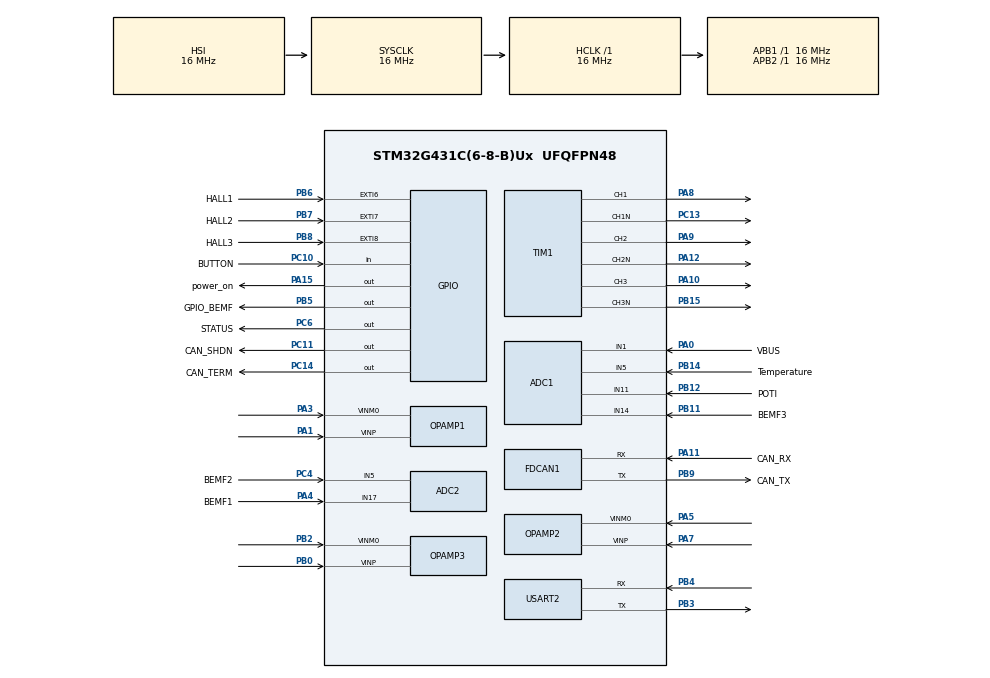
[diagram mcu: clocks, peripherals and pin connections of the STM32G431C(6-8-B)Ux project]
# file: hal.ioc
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ADC1.DMAAccessModeView=ENABLE
ADC1.DMAContinuousRequests=ENABLE
ADC1.DataAlign=ADC_DATAALIGN_LEFT
ADC1.EOCSelection=ADC_EOC_SEQ_CONV
ADC1.ExternalTrigConv=ADC_EXTERNALTRIG_T1_TRGO
ADC1.Mode=ADC_DUALMODE_REGSIMULT
ADC1.NbrOfConversionFlag=1
ADC1.Overrun=ADC_OVR_DATA_OVERWRITTEN
ADC1.master=1
ADC2.Channel-0\#ChannelRegularConversion=ADC_CHANNEL_5
ADC2.DMAAccessModeView=ENABLE
ADC2.DMAContinuousRequests=ENABLE
ADC2.DataAlign=ADC_DATAALIGN_LEFT
ADC2.EOCSelection=ADC_EOC_SINGLE_CONV
ADC2.Mode=ADC_DUALMODE_REGSIMULT
ADC2.NbrOfConversionFlag=1
Dma.ADC1.0.Direction=DMA_PERIPH_TO_MEMORY
Dma.ADC1.0.EventEnable=DISABLE
Dma.ADC1.0.Instance=DMA1_Channel1
Dma.ADC1.0.MemDataAlignment=DMA_MDATAALIGN_HALFWORD
Dma.ADC1.0.MemInc=DMA_MINC_ENABLE
Dma.ADC1.0.Mode=DMA_CIRCULAR
Dma.ADC1.0.PeriphDataAlignment=DMA_PDATAALIGN_HALFWORD
Dma.ADC1.0.PeriphInc=DMA_PINC_DISABLE
Dma.ADC1.0.Polarity=HAL_DMAMUX_REQ_GEN_RISING
Dma.ADC1.0.Priority=DMA_PRIORITY_LOW
Dma.ADC1.0.RequestNumber=1
Dma.ADC1.0.SignalID=NONE
Dma.ADC1.0.SyncEnable=DISABLE
Dma.ADC1.0.SyncPolarity=HAL_DMAMUX_SYNC_NO_EVENT
Dma.ADC1.0.SyncRequestNumber=1
Dma.ADC1.0.SyncSignalID=NONE
Dma.ADC2.1.Direction=DMA_PERIPH_TO_MEMORY
Dma.ADC2.1.EventEnable=DISABLE
Dma.ADC2.1.Instance=DMA1_Channel2
Dma.ADC2.1.MemDataAlignment=DMA_MDATAALIGN_HALFWORD
Dma.ADC2.1.MemInc=DMA_MINC_ENABLE
Dma.ADC2.1.Mode=DMA_CIRCULAR
Dma.ADC2.1.PeriphDataAlignment=DMA_PDATAALIGN_HALFWORD
Dma.ADC2.1.PeriphInc=DMA_PINC_DISABLE
Dma.ADC2.1.Polarity=HAL_DMAMUX_REQ_GEN_RISING
Dma.ADC2.1.Priority=DMA_PRIORITY_LOW
Dma.ADC2.1.RequestNumber=1
Dma.ADC2.1.SignalID=NONE
Dma.ADC2.1.SyncEnable=DISABLE
Dma.ADC2.1.SyncPolarity=HAL_DMAMUX_SYNC_NO_EVENT
Dma.ADC2.1.SyncRequestNumber=1
Dma.ADC2.1.SyncSignalID=NONE
Dma.Request0=ADC1
Dma.Request1=ADC2
Dma.Request2=USART2_RX
Dma.Request3=USART2_TX
Dma.USART2_RX.2.Direction=DMA_PERIPH_TO_MEMORY
Dma.USART2_RX.2.EventEnable=DISABLE
Dma.USART2_RX.2.Instance=DMA1_Channel3
Dma.USART2_RX.2.MemDataAlignment=DMA_MDATAALIGN_BYTE
Dma.USART2_RX.2.MemInc=DMA_MINC_ENABLE
Dma.USART2_RX.2.Mode=DMA_NORMAL
Dma.USART2_RX.2.PeriphDataAlignment=DMA_PDATAALIGN_BYTE
Dma.USART2_RX.2.PeriphInc=DMA_PINC_DISABLE
Dma.USART2_RX.2.Polarity=HAL_DMAMUX_REQ_GEN_RISING
Dma.USART2_RX.2.Priority=DMA_PRIORITY_LOW
Dma.USART2_RX.2.RequestNumber=1
Dma.USART2_RX.2.SignalID=NONE
Dma.USART2_RX.2.SyncEnable=DISABLE
Dma.USART2_RX.2.SyncPolarity=HAL_DMAMUX_SYNC_NO_EVENT
Dma.USART2_RX.2.SyncRequestNumber=1
Dma.USART2_RX.2.SyncSignalID=NONE
Dma.USART2_TX.3.Direction=DMA_MEMORY_TO_PERIPH
Dma.USART2_TX.3.EventEnable=DISABLE
Dma.USART2_TX.3.Instance=DMA1_Channel4
Dma.USART2_TX.3.MemDataAlignment=DMA_MDATAALIGN_BYTE
Dma.USART2_TX.3.MemInc=DMA_MINC_ENABLE
Dma.USART2_TX.3.Mode=DMA_NORMAL
Dma.USART2_TX.3.PeriphDataAlignment=DMA_PDATAALIGN_BYTE
Dma.USART2_TX.3.PeriphInc=DMA_PINC_DISABLE
Dma.USART2_TX.3.Polarity=HAL_DMAMUX_REQ_GEN_RISING
Dma.USART2_TX.3.Priority=DMA_PRIORITY_LOW
Dma.USART2_TX.3.RequestNumber=1
Dma.USART2_TX.3.SignalID=NONE
Dma.USART2_TX.3.SyncEnable=DISABLE
Dma.USART2_TX.3.SyncPolarity=HAL_DMAMUX_SYNC_NO_EVENT
Dma.USART2_TX.3.SyncRequestNumber=1
Dma.USART2_TX.3.SyncSignalID=NONE
FDCAN1.CalculateBaudRateNominal=333333
FDCAN1.CalculateTimeBitNominal=3000
FDCAN1.CalculateTimeQuantumNominal=1000.0
Mcu.Family=STM32G4
Mcu.Name=STM32G431C(6-8-B)Ux
Mcu.Package=UFQFPN48
NVIC.ADC1_2_IRQn=true\:0\:0\:false\:false\:true\:true\:true\:true
NVIC.DMA1_Channel1_IRQn=true\:0\:0\:false\:false\:true\:false\:true\:true
NVIC.DMA1_Channel2_IRQn=true\:0\:0\:false\:false\:true\:false\:true\:true
NVIC.DMA1_Channel3_IRQn=true\:0\:0\:false\:false\:true\:false\:true\:true
NVIC.DMA1_Channel4_IRQn=true\:0\:0\:false\:false\:true\:false\:true\:true
NVIC.EXTI9_5_IRQn=true\:0\:0\:false\:false\:true\:true\:true\:true
NVIC.PriorityGroup=NVIC_PRIORITYGROUP_4
NVIC.TIM1_UP_TIM16_IRQn=true\:0\:0\:false\:false\:true\:true\:true\:true
NVIC.USART2_IRQn=true\:0\:0\:false\:false\:true\:true\:true\:true
PA0.GPIO_Label=VBUS
PA0.GPIO_Mode=GPIO_MODE_ANALOG
PA0.GPIO_PuPd=GPIO_NOPULL
PA0.Mode=IN1-Single-Ended
PA0.Signal=ADC1_IN1
PA1.Mode=standalone Internally connected_IO
PA1.Signal=OPAMP1_VINP
PA10.GPIO_PuPd=GPIO_PULLDOWN
PA10.Signal=S_TIM1_CH3
PA11.GPIO_Label=CAN_RX
PA11.Mode=FDCAN_Activate
PA11.Signal=FDCAN1_RX
PA12.GPIO_PuPd=GPIO_PULLDOWN
PA12.Mode=PWM Generation2 CH2 CH2N
PA12.Signal=TIM1_CH2N
PA13.Signal=SYS_JTMS-SWDIO
PA14.Signal=SYS_JTCK-SWCLK
PA15.GPIO_Label=power_on
PA15.GPIO_ModeDefaultOutputPP=GPIO_MODE_OUTPUT_OD
PA15.GPIO_PuPd=GPIO_NOPULL
PA15.PinState=GPIO_PIN_SET
PA15.Signal=GPIO_Output
PA3.Mode=standalone Internally connected_IO
PA3.Signal=OPAMP1_VINM0
PA4.GPIO_Label=BEMF1
PA4.GPIO_Mode=GPIO_MODE_ANALOG
PA4.GPIO_PuPd=GPIO_NOPULL
PA4.Mode=IN17-Single-Ended
PA4.Signal=ADC2_IN17
PA5.Mode=standalone Internally connected_IO
PA5.Signal=OPAMP2_VINM0
PA7.Mode=standalone Internally connected_IO
PA7.Signal=OPAMP2_VINP
PA8.GPIO_PuPd=GPIO_PULLDOWN
PA8.Signal=S_TIM1_CH1
PA9.GPIO_PuPd=GPIO_PULLDOWN
PA9.Signal=S_TIM1_CH2
PB0.Mode=standalone Internally connected_IO
PB0.Signal=OPAMP3_VINP
PB11.GPIO_Label=BEMF3
PB11.GPIO_Mode=GPIO_MODE_ANALOG
PB11.GPIO_PuPd=GPIO_NOPULL
PB11.Mode=IN14-Single-Ended
PB11.Signal=ADC1_IN14
PB12.GPIO_Label=POTI
PB12.GPIO_Mode=GPIO_MODE_ANALOG
PB12.GPIO_PuPd=GPIO_NOPULL
PB12.Mode=IN11-Single-Ended
PB12.Signal=ADC1_IN11
PB14.GPIO_Label=Temperature
PB14.GPIO_Mode=GPIO_MODE_ANALOG
PB14.GPIO_PuPd=GPIO_NOPULL
PB14.Mode=IN5-Single-Ended
PB14.Signal=ADC1_IN5
PB15.GPIO_PuPd=GPIO_PULLDOWN
PB15.Mode=PWM Generation3 CH3 CH3N
PB15.Signal=TIM1_CH3N
PB2.Mode=standalone Internally connected_IO
PB2.Signal=OPAMP3_VINM0
PB3.Mode=Asynchronous
PB3.Signal=USART2_TX
PB4.Mode=Asynchronous
PB4.Signal=USART2_RX
PB5.GPIO_Label=GPIO_BEMF
PB5.Signal=GPIO_Output
PB6.GPIO_Label=HALL1
PB6.GPIO_ModeDefaultEXTI=GPIO_MODE_IT_RISING_FALLING
PB6.Signal=GPXTI6
PB7.GPIO_Label=HALL2
PB7.GPIO_ModeDefaultEXTI=GPIO_MODE_IT_RISING_FALLING
PB7.Signal=GPXTI7
PB8-BOOT0.GPIO_Label=HALL3
PB8-BOOT0.GPIO_ModeDefaultEXTI=GPIO_MODE_IT_RISING_FALLING
PB8-BOOT0.Signal=GPXTI8
PB9.GPIO_Label=CAN_TX
PB9.Mode=FDCAN_Activate
PB9.Signal=FDCAN1_TX
PC10.GPIO_Label=BUTTON
PC10.Signal=GPIO_Input
PC11.GPIO_Label=CAN_SHDN
PC11.Signal=GPIO_Output
PC13.GPIO_PuPd=GPIO_PULLDOWN
PC13.Mode=PWM Generation1 CH1 CH1N
PC13.Signal=TIM1_CH1N
PC14-OSC32_IN.GPIO_Label=CAN_TERM
PC14-OSC32_IN.Signal=GPIO_Output
PC4.GPIO_Label=BEMF2
PC4.GPIO_Mode=GPIO_MODE_ANALOG
PC4.GPIO_PuPd=GPIO_NOPULL
PC4.Mode=IN5-Single-Ended
PC4.Signal=ADC2_IN5
PC6.GPIO_Label=STATUS
PC6.Signal=GPIO_Output
PF0-OSC_IN.Mode=HSE-External-Oscillator
PF0-OSC_IN.Signal=RCC_OSC_IN
PF1-OSC_OUT.Mode=HSE-External-Oscillator
PF1-OSC_OUT.Signal=RCC_OSC_OUT
ProjectManager.HeapSize=0x200
ProjectManager.StackSize=0x400
ProjectManager.TargetToolchain=CMake
RCC.ADC12Freq_Value=16000000
RCC.AHBFreq_Value=16000000
RCC.APB1Freq_Value=16000000
RCC.APB1TimFreq_Value=16000000
RCC.APB2Freq_Value=16000000
RCC.APB2TimFreq_Value=16000000
RCC.CortexFreq_Value=16000000
RCC.EXTERNAL_CLOCK_VALUE=12288000
RCC.HCLKFreq_Value=16000000
RCC.HSE_VALUE=8000000
RCC.HSI48_VALUE=48000000
RCC.HSI_VALUE=16000000
RCC.LSE_VALUE=32768
RCC.PLLM=RCC_PLLM_DIV4
RCC.PLLN=85
RCC.SYSCLKFreq_VALUE=16000000
RCC.USBFreq_Value=170000000
RCC.VCOOutputFreq_Value=340000000
SH.S_TIM1_CH1.0=TIM1_CH1,PWM Generation1 CH1 CH1N
SH.S_TIM1_CH2.0=TIM1_CH2,PWM Generation2 CH2 CH2N
SH.S_TIM1_CH3.0=TIM1_CH3,PWM Generation3 CH3 CH3N
TIM1.Channel-PWM\ Generation1\ CH1\ CH1N=TIM_CHANNEL_1
TIM1.Channel-PWM\ Generation2\ CH2\ CH2N=TIM_CHANNEL_2
TIM1.Channel-PWM\ Generation3\ CH3\ CH3N=TIM_CHANNEL_3
TIM1.DeadTime=0x1F
TIM1.TIM_MasterOutputTrigger=TIM_TRGO_UPDATE
USART2.VirtualMode-Asynchronous=VM_ASYNC
VP_ADC1_OPAMP_INTERNAL1.Mode=IN-OPAMP1
VP_ADC1_Vref_Input.Mode=IN-Vrefint
VP_ADC2_OPAMP_INTERNAL2.Mode=IN-OPAMP2
VP_ADC2_OPAMP_INTERNAL3.Mode=IN-OPAMP3
VP_CORDIC_VS_CORDIC.Mode=CORDIC_Activate
VP_CRC_VS_CRC.Mode=CRC_Activate
VP_FMAC_VS_FMAC.Mode=FMAC_Activate
VP_SYS_VS_DBSignals.Mode=DisableDeadBatterySignals
VP_TIM1_VS_ClockSourceINT.Mode=Internal
board=custom

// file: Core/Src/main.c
/* USER CODE BEGIN Header */
/**
 ******************************************************************************
 * @file           : main.c
 * @brief          : Main program body
 ******************************************************************************
 * @attention
 *
 * Copyright (c) 2025 STMicroelectronics.
 * All rights reserved.
 *
 * This software is licensed under terms that can be found in the LICENSE file
 * in the root directory of this software component.
 * If no LICENSE file comes with this software, it is provided AS-IS.
 *
 ******************************************************************************
 */
/* USER CODE END Header */
#include "main.h"
#include "adc.h"
#include "cordic.h"
#include "crc.h"
#include "dma.h"
#include "fdcan.h"
#include "fmac.h"
#include "gpio.h"
#include "opamp.h"
#include "tim.h"
#include "usart.h"

void SystemClock_Config(void);

/* USER CODE BEGIN 0 */
#if 0
/* USER CODE END 0 */

int main(void)
{

  /* MCU Configuration--------------------------------------------------------*/

  /* Reset of all peripherals, Initializes the Flash interface and the Systick. */
  HAL_Init();

  /* Configure the system clock */
  SystemClock_Config();

  /* Initialize all configured peripherals */
  MX_GPIO_Init();
  MX_DMA_Init();
  MX_ADC1_Init();
  MX_ADC2_Init();
  MX_CORDIC_Init();
  MX_CRC_Init();
  MX_FDCAN1_Init();
  MX_FMAC_Init();
  MX_OPAMP1_Init();
  MX_OPAMP2_Init();
  MX_OPAMP3_Init();
  MX_TIM1_Init();
  MX_USART2_UART_Init();

  /* Infinite loop */
  while (1)
  {

    /* USER CODE BEGIN 3 */
  }
#endif
void dummy()
{
    /* USER CODE END 3 */
}

void SystemClock_Config(void)
{
    RCC_OscInitTypeDef RCC_OscInitStruct = {0};
    RCC_ClkInitTypeDef RCC_ClkInitStruct = {0};

    /** Configure the main internal regulator output voltage
     */
    HAL_PWREx_ControlVoltageScaling(PWR_REGULATOR_VOLTAGE_SCALE1);

    /** Initializes the RCC Oscillators according to the specified parameters
     * in the RCC_OscInitTypeDef structure.
     */
    RCC_OscInitStruct.OscillatorType = RCC_OSCILLATORTYPE_HSI;
    RCC_OscInitStruct.HSIState = RCC_HSI_ON;
    RCC_OscInitStruct.HSICalibrationValue = RCC_HSICALIBRATION_DEFAULT;
    RCC_OscInitStruct.PLL.PLLState = RCC_PLL_NONE;
    if (HAL_RCC_OscConfig(&RCC_OscInitStruct) != HAL_OK)
    {
        Error_Handler();
    }

    /** Initializes the CPU, AHB and APB buses clocks
     */
    RCC_ClkInitStruct.ClockType = RCC_CLOCKTYPE_HCLK | RCC_CLOCKTYPE_SYSCLK | RCC_CLOCKTYPE_PCLK1 | RCC_CLOCKTYPE_PCLK2;
    RCC_ClkInitStruct.SYSCLKSource = RCC_SYSCLKSOURCE_HSI;
    RCC_ClkInitStruct.AHBCLKDivider = RCC_SYSCLK_DIV1;
    RCC_ClkInitStruct.APB1CLKDivider = RCC_HCLK_DIV1;
    RCC_ClkInitStruct.APB2CLKDivider = RCC_HCLK_DIV1;

    if (HAL_RCC_ClockConfig(&RCC_ClkInitStruct, FLASH_LATENCY_0) != HAL_OK)
    {
        Error_Handler();
    }
}

void Error_Handler(void)
{
    __disable_irq();
    while (1)
    {
    }
}
